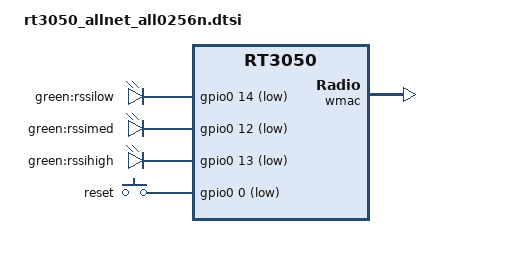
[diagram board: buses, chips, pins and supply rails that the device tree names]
#include "rt3050.dtsi"

#include <dt-bindings/gpio/gpio.h>
#include <dt-bindings/input/input.h>

/ {
	compatible = "allnet,all0256n", "ralink,rt3050-soc";

	leds {
		compatible = "gpio-leds";

		rssilow {
			label = "green:rssilow";
			gpios = <&gpio0 14 GPIO_ACTIVE_LOW>;
		};

		rssimed {
			label = "green:rssimed";
			gpios = <&gpio0 12 GPIO_ACTIVE_LOW>;
		};

		rssihigh {
			label = "green:rssihigh";
			gpios = <&gpio0 13 GPIO_ACTIVE_LOW>;
		};
	};

	keys {
		compatible = "gpio-keys-polled";
		poll-interval = <20>;

		reset {
			label = "reset";
			gpios = <&gpio0 0 GPIO_ACTIVE_LOW>;
			linux,code = <KEY_RESTART>;
		};
	};
};

&state_default {
	gpio {
		groups = "i2c", "jtag", "rgmii", "mdio", "uartf";
		function = "gpio";
	};
};

&ethernet {
	mtd-mac-address = <&factory 0x28>;
};

&esw {
	mediatek,portmap = <0x3f>;
};

&wmac {
	ralink,mtd-eeprom = <&factory 0x0>;
};
